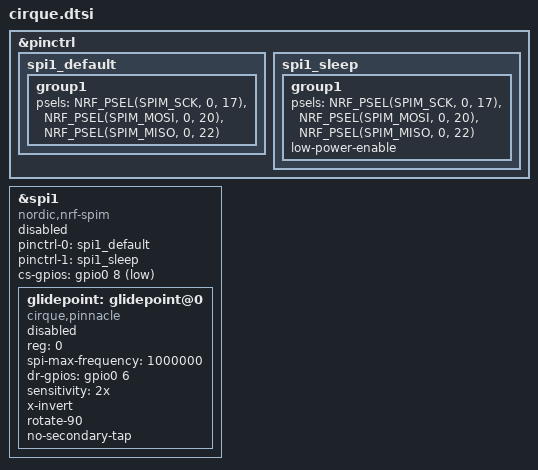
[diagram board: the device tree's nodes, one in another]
&pinctrl {
    spi1_default: spi1_default {
        group1 {
            psels = <NRF_PSEL(SPIM_SCK, 0, 17)>,
                <NRF_PSEL(SPIM_MOSI, 0, 20)>,
                <NRF_PSEL(SPIM_MISO, 0, 22)>;
        };
    };
    
    spi1_sleep: spi1_sleep {
        group1 {
            psels = <NRF_PSEL(SPIM_SCK, 0, 17)>,
                <NRF_PSEL(SPIM_MOSI, 0, 20)>,
                <NRF_PSEL(SPIM_MISO, 0, 22)>;
            low-power-enable;
        };
    };
};

&spi1 {
    compatible = "nordic,nrf-spim";
    status = "disabled";
    pinctrl-0 = <&spi1_default>;
    pinctrl-1 = <&spi1_sleep>;
    pinctrl-names = "default", "sleep";
    cs-gpios = <&gpio0 8 GPIO_ACTIVE_LOW>;

    glidepoint: glidepoint@0 {
        compatible = "cirque,pinnacle";
        status = "disabled";
        reg = <0>;
        spi-max-frequency = <1000000>;
        dr-gpios = <&gpio0 6 (GPIO_ACTIVE_HIGH | GPIO_PULL_UP)>;

        sensitivity = "2x";
        x-invert;
        rotate-90;
        no-secondary-tap;
        //sleep;
        //no-taps;
    };
};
